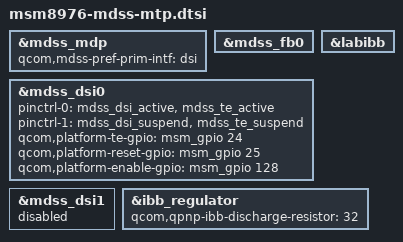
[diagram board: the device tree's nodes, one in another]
/*
 * Copyright (c) 2015-2016, The Linux Foundation. All rights reserved.
 *
 * This program is free software; you can redistribute it and/or modify
 * it under the terms of the GNU General Public License version 2 and
 * only version 2 as published by the Free Software Foundation.
 *
 * This program is distributed in the hope that it will be useful,
 * but WITHOUT ANY WARRANTY; without even the implied warranty of
 * MERCHANTABILITY or FITNESS FOR A PARTICULAR PURPOSE.  See the
 * GNU General Public License for more details.
 */

#include "msm8976-mdss-panels.dtsi"

&mdss_mdp {
	qcom,mdss-pref-prim-intf = "dsi";
};

&mdss_fb0 {
	/delete-node/ qcom,cont-splash-memory;
};

&mdss_dsi0 {
	pinctrl-names = "mdss_default", "mdss_sleep";
	pinctrl-0 = <&mdss_dsi_active &mdss_te_active>;
	pinctrl-1 = <&mdss_dsi_suspend &mdss_te_suspend>;

	qcom,platform-te-gpio = <&msm_gpio 24 0>;
	qcom,platform-reset-gpio = <&msm_gpio 25 0>;
	qcom,platform-enable-gpio = <&msm_gpio 128 0>;
};

&mdss_dsi1 {
	status = "disabled";
};

&labibb {
	status = "ok";
};

&ibb_regulator {
	qcom,qpnp-ibb-discharge-resistor = <32>;
};

/delete-node/ &cont_splash_mem;
